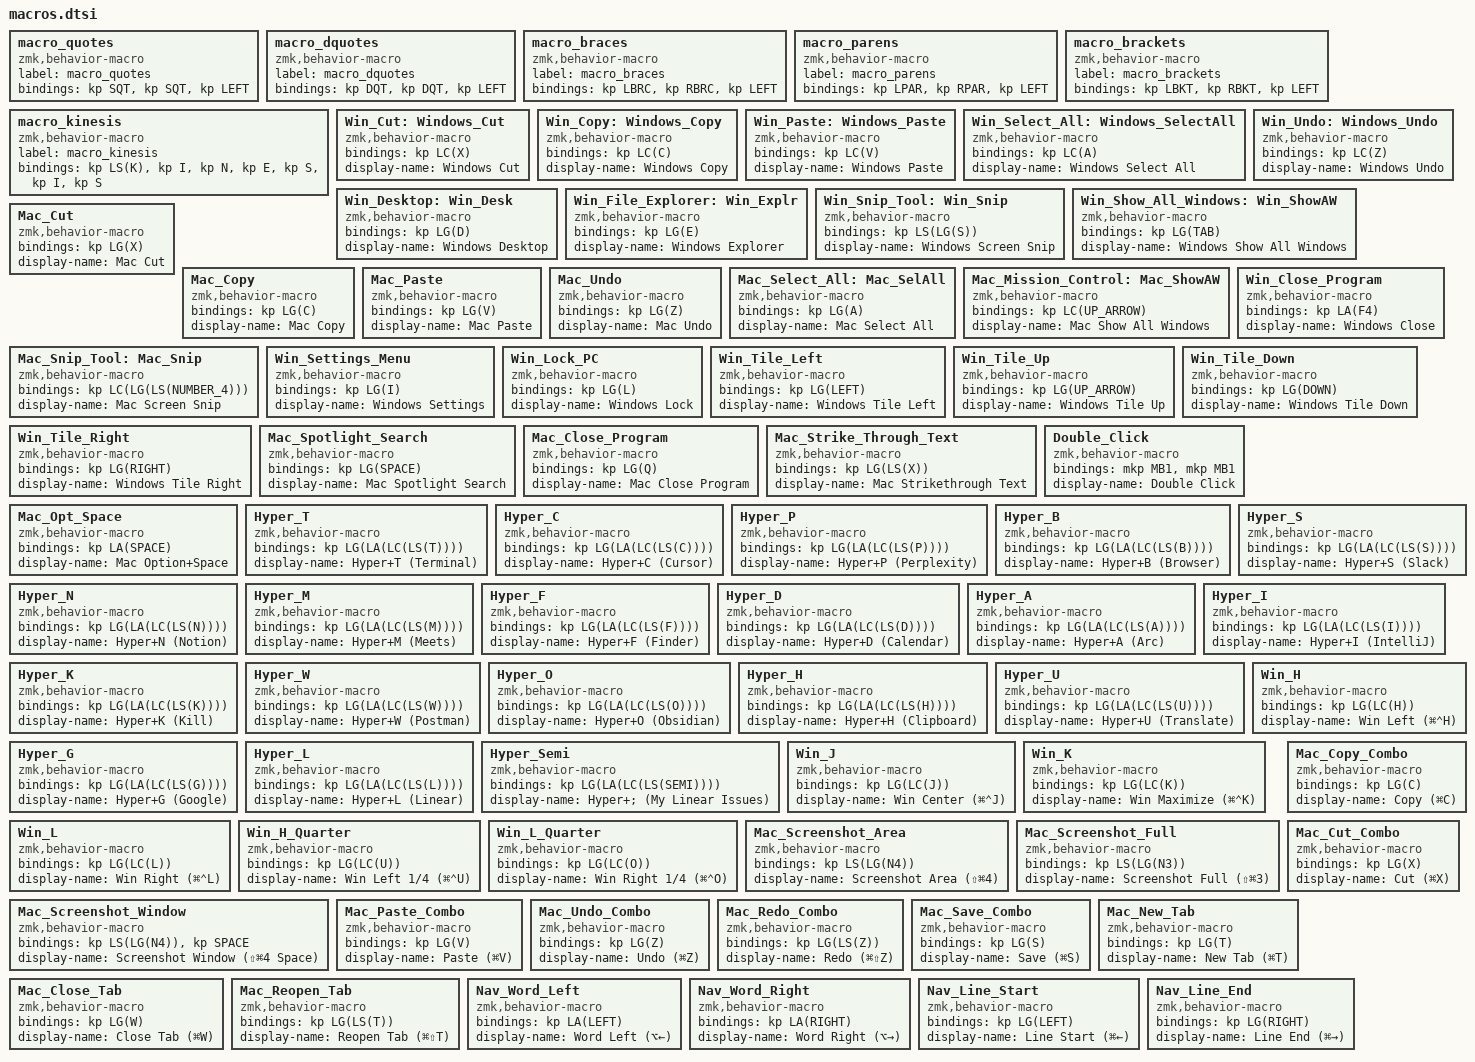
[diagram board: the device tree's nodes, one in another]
  macro_quotes: macro_quotes {
    compatible = "zmk,behavior-macro";
    label = "macro_quotes";
    #binding-cells = <0>;
    bindings = <&kp SQT>, <&kp SQT>, <&kp LEFT>;
  };
  macro_dquotes: macro_dquotes {
    compatible = "zmk,behavior-macro";
    label = "macro_dquotes";
    #binding-cells = <0>;
    bindings = <&kp DQT>, <&kp DQT>, <&kp LEFT>;
  };
  macro_braces: macro_braces {
    compatible = "zmk,behavior-macro";
    label = "macro_braces";
    #binding-cells = <0>;
    bindings = <&kp LBRC>, <&kp RBRC>, <&kp LEFT>;
  };
  macro_parens: macro_parens {
    compatible = "zmk,behavior-macro";
    label = "macro_parens";
    #binding-cells = <0>;
    bindings = <&kp LPAR>, <&kp RPAR>, <&kp LEFT>;
  };
  macro_brackets: macro_brackets {
    compatible = "zmk,behavior-macro";
    label = "macro_brackets";
    #binding-cells = <0>;
    bindings = <&kp LBKT>, <&kp RBKT>, <&kp LEFT>;
  };
  macro_kinesis: macro_kinesis {
    compatible = "zmk,behavior-macro";
    label = "macro_kinesis";
    #binding-cells = <0>;
    bindings = <&kp LS(K)>, <&kp I>, <&kp N>, <&kp E>, <&kp S>, <&kp I>, <&kp S>;
  };
  Win_Cut: Windows_Cut {
    compatible = "zmk,behavior-macro";
    #binding-cells = <0>;
    bindings = <&kp LC(X)>;
    display-name = "Windows Cut";
  };

  Win_Copy: Windows_Copy {
    compatible = "zmk,behavior-macro";
    #binding-cells = <0>;
    bindings = <&kp LC(C)>;
    display-name = "Windows Copy";
  };

  Win_Paste: Windows_Paste {
    compatible = "zmk,behavior-macro";
    #binding-cells = <0>;
    bindings = <&kp LC(V)>;
    display-name = "Windows Paste";
  };

  Win_Select_All: Windows_SelectAll {
      compatible = "zmk,behavior-macro";
      #binding-cells = <0>;
      bindings = <&kp LC(A)>;
      display-name = "Windows Select All";
  };

  Win_Undo: Windows_Undo {
    compatible = "zmk,behavior-macro";
    #binding-cells = <0>;
    bindings = <&kp LC(Z)>;
    display-name = "Windows Undo";
  };

  Win_Desktop: Win_Desk {
    compatible = "zmk,behavior-macro";
    #binding-cells = <0>;
    bindings = <&kp LG(D)>;
    display-name = "Windows Desktop";
  };

  Win_File_Explorer: Win_Explr {
    compatible = "zmk,behavior-macro";
    #binding-cells = <0>;
    bindings = <&kp LG(E)>;
    display-name = "Windows Explorer";
  };

  Win_Snip_Tool: Win_Snip {
    compatible = "zmk,behavior-macro";
    #binding-cells = <0>;
    bindings = <&kp LS(LG(S))>;
    display-name = "Windows Screen Snip";
  };

  Win_Show_All_Windows: Win_ShowAW {
    compatible = "zmk,behavior-macro";
    #binding-cells = <0>;
    bindings = <&kp LG(TAB)>;
    display-name = "Windows Show All Windows";
  };

  Mac_Cut: Mac_Cut {
    compatible = "zmk,behavior-macro";
    #binding-cells = <0>;
    bindings = <&kp LG(X)>;
    display-name = "Mac Cut";
  };

  Mac_Copy: Mac_Copy {
    compatible = "zmk,behavior-macro";
    #binding-cells = <0>;
    bindings = <&kp LG(C)>;
    display-name = "Mac Copy";
  };

  Mac_Paste: Mac_Paste {
    compatible = "zmk,behavior-macro";
    #binding-cells = <0>;
    bindings = <&kp LG(V)>;
    display-name = "Mac Paste";
  };

  Mac_Undo: Mac_Undo {
    compatible = "zmk,behavior-macro";
    #binding-cells = <0>;
    bindings = <&kp LG(Z)>;
    display-name = "Mac Undo";
  };

  Mac_Select_All: Mac_SelAll {
    compatible = "zmk,behavior-macro";
    #binding-cells = <0>;
    bindings = <&kp LG(A)>;
    display-name = "Mac Select All";
  };

  Mac_Mission_Control: Mac_ShowAW {
    compatible = "zmk,behavior-macro";
    #binding-cells = <0>;
    bindings = <&kp LC(UP_ARROW)>;
    display-name = "Mac Show All Windows";
  };

  Mac_Snip_Tool: Mac_Snip {
    compatible = "zmk,behavior-macro";
    #binding-cells = <0>;
    bindings = <&kp LC(LG(LS(NUMBER_4)))>;
    display-name = "Mac Screen Snip";
  };

  Win_Close_Program: Win_Close_Program {
    compatible = "zmk,behavior-macro";
    #binding-cells = <0>;
    bindings = <&kp LA(F4)>;
    display-name = "Windows Close";
  };

  Win_Settings_Menu: Win_Settings_Menu {
    compatible = "zmk,behavior-macro";
    #binding-cells = <0>;
    bindings = <&kp LG(I)>;
    display-name = "Windows Settings";
  };

  Win_Lock_PC: Win_Lock_PC {
    compatible = "zmk,behavior-macro";
    #binding-cells = <0>;
    bindings = <&kp LG(L)>;
    display-name = "Windows Lock";
  };

  Win_Tile_Left: Win_Tile_Left {
    compatible = "zmk,behavior-macro";
    #binding-cells = <0>;
    bindings = <&kp LG(LEFT)>;
    display-name = "Windows Tile Left";
  };

  Win_Tile_Up: Win_Tile_Up {
    compatible = "zmk,behavior-macro";
    #binding-cells = <0>;
    bindings = <&kp LG(UP_ARROW)>;
    display-name = "Windows Tile Up";
  };

  Win_Tile_Down: Win_Tile_Down {
    compatible = "zmk,behavior-macro";
    #binding-cells = <0>;
    bindings = <&kp LG(DOWN)>;
    display-name = "Windows Tile Down";
  };

  Win_Tile_Right: Win_Tile_Right {
    compatible = "zmk,behavior-macro";
    #binding-cells = <0>;
    bindings = <&kp LG(RIGHT)>;
    display-name = "Windows Tile Right";
  };

  Mac_Spotlight_Search: Mac_Spotlight_Search {
    compatible = "zmk,behavior-macro";
    #binding-cells = <0>;
    bindings = <&kp LG(SPACE)>;
    display-name = "Mac Spotlight Search";
  };

  Mac_Close_Program: Mac_Close_Program {
    compatible = "zmk,behavior-macro";
    #binding-cells = <0>;
    bindings = <&kp LG(Q)>;
    display-name = "Mac Close Program";
  };

  Mac_Strike_Through_Text: Mac_Strike_Through_Text {
    compatible = "zmk,behavior-macro";
    #binding-cells = <0>;
    bindings = <&kp LG(LS(X))>;
    display-name = "Mac Strikethrough Text";
  };

  Double_Click: Double_Click {
    compatible = "zmk,behavior-macro";
    #binding-cells = <0>;
    bindings = <&mkp MB1 &mkp MB1>;
    display-name = "Double Click";
  };

  Mac_Opt_Space: Mac_Opt_Space {
    compatible = "zmk,behavior-macro";
    #binding-cells = <0>;
    bindings = <&kp LA(SPACE)>;
    display-name = "Mac Option+Space";
  };

  // Hyper key app launchers (Cmd+Opt+Ctrl+Shift+Letter)
  Hyper_T: Hyper_T {
    compatible = "zmk,behavior-macro";
    #binding-cells = <0>;
    bindings = <&kp LG(LA(LC(LS(T))))>;
    display-name = "Hyper+T (Terminal)";
  };

  Hyper_C: Hyper_C {
    compatible = "zmk,behavior-macro";
    #binding-cells = <0>;
    bindings = <&kp LG(LA(LC(LS(C))))>;
    display-name = "Hyper+C (Cursor)";
  };

  Hyper_P: Hyper_P {
    compatible = "zmk,behavior-macro";
    #binding-cells = <0>;
    bindings = <&kp LG(LA(LC(LS(P))))>;
    display-name = "Hyper+P (Perplexity)";
  };

  Hyper_B: Hyper_B {
    compatible = "zmk,behavior-macro";
    #binding-cells = <0>;
    bindings = <&kp LG(LA(LC(LS(B))))>;
    display-name = "Hyper+B (Browser)";
  };

  Hyper_S: Hyper_S {
    compatible = "zmk,behavior-macro";
    #binding-cells = <0>;
    bindings = <&kp LG(LA(LC(LS(S))))>;
    display-name = "Hyper+S (Slack)";
  };

  Hyper_N: Hyper_N {
    compatible = "zmk,behavior-macro";
    #binding-cells = <0>;
    bindings = <&kp LG(LA(LC(LS(N))))>;
    display-name = "Hyper+N (Notion)";
  };

  Hyper_M: Hyper_M {
    compatible = "zmk,behavior-macro";
    #binding-cells = <0>;
    bindings = <&kp LG(LA(LC(LS(M))))>;
    display-name = "Hyper+M (Meets)";
  };

  Hyper_F: Hyper_F {
    compatible = "zmk,behavior-macro";
    #binding-cells = <0>;
    bindings = <&kp LG(LA(LC(LS(F))))>;
    display-name = "Hyper+F (Finder)";
  };

  Hyper_D: Hyper_D {
    compatible = "zmk,behavior-macro";
    #binding-cells = <0>;
    bindings = <&kp LG(LA(LC(LS(D))))>;
    display-name = "Hyper+D (Calendar)";
  };

  Hyper_A: Hyper_A {
    compatible = "zmk,behavior-macro";
    #binding-cells = <0>;
    bindings = <&kp LG(LA(LC(LS(A))))>;
    display-name = "Hyper+A (Arc)";
  };

  Hyper_I: Hyper_I {
    compatible = "zmk,behavior-macro";
    #binding-cells = <0>;
    bindings = <&kp LG(LA(LC(LS(I))))>;
    display-name = "Hyper+I (IntelliJ)";
  };

  Hyper_K: Hyper_K {
    compatible = "zmk,behavior-macro";
    #binding-cells = <0>;
    bindings = <&kp LG(LA(LC(LS(K))))>;
    display-name = "Hyper+K (Kill)";
  };

  Hyper_W: Hyper_W {
    compatible = "zmk,behavior-macro";
    #binding-cells = <0>;
    bindings = <&kp LG(LA(LC(LS(W))))>;
    display-name = "Hyper+W (Postman)";
  };

  Hyper_O: Hyper_O {
    compatible = "zmk,behavior-macro";
    #binding-cells = <0>;
    bindings = <&kp LG(LA(LC(LS(O))))>;
    display-name = "Hyper+O (Obsidian)";
  };

  Hyper_H: Hyper_H {
    compatible = "zmk,behavior-macro";
    #binding-cells = <0>;
    bindings = <&kp LG(LA(LC(LS(H))))>;
    display-name = "Hyper+H (Clipboard)";
  };

  Hyper_U: Hyper_U {
    compatible = "zmk,behavior-macro";
    #binding-cells = <0>;
    bindings = <&kp LG(LA(LC(LS(U))))>;
    display-name = "Hyper+U (Translate)";
  };

  Hyper_G: Hyper_G {
    compatible = "zmk,behavior-macro";
    #binding-cells = <0>;
    bindings = <&kp LG(LA(LC(LS(G))))>;
    display-name = "Hyper+G (Google)";
  };

  Hyper_L: Hyper_L {
    compatible = "zmk,behavior-macro";
    #binding-cells = <0>;
    bindings = <&kp LG(LA(LC(LS(L))))>;
    display-name = "Hyper+L (Linear)";
  };

  Hyper_Semi: Hyper_Semi {
    compatible = "zmk,behavior-macro";
    #binding-cells = <0>;
    bindings = <&kp LG(LA(LC(LS(SEMI))))>;
    display-name = "Hyper+; (My Linear Issues)";
  };

  // Window Management shortcuts (Cmd+Ctrl+Letter)
  Win_H: Win_H {
    compatible = "zmk,behavior-macro";
    #binding-cells = <0>;
    bindings = <&kp LG(LC(H))>;
    display-name = "Win Left (⌘⌃H)";
  };

  Win_J: Win_J {
    compatible = "zmk,behavior-macro";
    #binding-cells = <0>;
    bindings = <&kp LG(LC(J))>;
    display-name = "Win Center (⌘⌃J)";
  };

  Win_K: Win_K {
    compatible = "zmk,behavior-macro";
    #binding-cells = <0>;
    bindings = <&kp LG(LC(K))>;
    display-name = "Win Maximize (⌘⌃K)";
  };

  Win_L: Win_L {
    compatible = "zmk,behavior-macro";
    #binding-cells = <0>;
    bindings = <&kp LG(LC(L))>;
    display-name = "Win Right (⌘⌃L)";
  };

  Win_H_Quarter: Win_H_Quarter {
    compatible = "zmk,behavior-macro";
    #binding-cells = <0>;
    bindings = <&kp LG(LC(U))>;
    display-name = "Win Left 1/4 (⌘⌃U)";
  };

  Win_L_Quarter: Win_L_Quarter {
    compatible = "zmk,behavior-macro";
    #binding-cells = <0>;
    bindings = <&kp LG(LC(O))>;
    display-name = "Win Right 1/4 (⌘⌃O)";
  };

  // Screenshot macros
  Mac_Screenshot_Area: Mac_Screenshot_Area {
    compatible = "zmk,behavior-macro";
    #binding-cells = <0>;
    bindings = <&kp LS(LG(N4))>;
    display-name = "Screenshot Area (⇧⌘4)";
  };

  Mac_Screenshot_Full: Mac_Screenshot_Full {
    compatible = "zmk,behavior-macro";
    #binding-cells = <0>;
    bindings = <&kp LS(LG(N3))>;
    display-name = "Screenshot Full (⇧⌘3)";
  };

  Mac_Screenshot_Window: Mac_Screenshot_Window {
    compatible = "zmk,behavior-macro";
    #binding-cells = <0>;
    bindings = <&kp LS(LG(N4)) &kp SPACE>;
    display-name = "Screenshot Window (⇧⌘4 Space)";
  };

  // Common action macros for combos
  Mac_Copy_Combo: Mac_Copy_Combo {
    compatible = "zmk,behavior-macro";
    #binding-cells = <0>;
    bindings = <&kp LG(C)>;
    display-name = "Copy (⌘C)";
  };

  Mac_Paste_Combo: Mac_Paste_Combo {
    compatible = "zmk,behavior-macro";
    #binding-cells = <0>;
    bindings = <&kp LG(V)>;
    display-name = "Paste (⌘V)";
  };

  Mac_Cut_Combo: Mac_Cut_Combo {
    compatible = "zmk,behavior-macro";
    #binding-cells = <0>;
    bindings = <&kp LG(X)>;
    display-name = "Cut (⌘X)";
  };

  Mac_Undo_Combo: Mac_Undo_Combo {
    compatible = "zmk,behavior-macro";
    #binding-cells = <0>;
    bindings = <&kp LG(Z)>;
    display-name = "Undo (⌘Z)";
  };

  Mac_Redo_Combo: Mac_Redo_Combo {
    compatible = "zmk,behavior-macro";
    #binding-cells = <0>;
    bindings = <&kp LG(LS(Z))>;
    display-name = "Redo (⌘⇧Z)";
  };

  Mac_Save_Combo: Mac_Save_Combo {
    compatible = "zmk,behavior-macro";
    #binding-cells = <0>;
    bindings = <&kp LG(S)>;
    display-name = "Save (⌘S)";
  };

  Mac_New_Tab: Mac_New_Tab {
    compatible = "zmk,behavior-macro";
    #binding-cells = <0>;
    bindings = <&kp LG(T)>;
    display-name = "New Tab (⌘T)";
  };

  Mac_Close_Tab: Mac_Close_Tab {
    compatible = "zmk,behavior-macro";
    #binding-cells = <0>;
    bindings = <&kp LG(W)>;
    display-name = "Close Tab (⌘W)";
  };

  Mac_Reopen_Tab: Mac_Reopen_Tab {
    compatible = "zmk,behavior-macro";
    #binding-cells = <0>;
    bindings = <&kp LG(LS(T))>;
    display-name = "Reopen Tab (⌘⇧T)";
  };

  // Navigation macros
  Nav_Word_Left: Nav_Word_Left {
    compatible = "zmk,behavior-macro";
    #binding-cells = <0>;
    bindings = <&kp LA(LEFT)>;
    display-name = "Word Left (⌥←)";
  };

  Nav_Word_Right: Nav_Word_Right {
    compatible = "zmk,behavior-macro";
    #binding-cells = <0>;
    bindings = <&kp LA(RIGHT)>;
    display-name = "Word Right (⌥→)";
  };

  Nav_Line_Start: Nav_Line_Start {
    compatible = "zmk,behavior-macro";
    #binding-cells = <0>;
    bindings = <&kp LG(LEFT)>;
    display-name = "Line Start (⌘←)";
  };

  Nav_Line_End: Nav_Line_End {
    compatible = "zmk,behavior-macro";
    #binding-cells = <0>;
    bindings = <&kp LG(RIGHT)>;
    display-name = "Line End (⌘→)";
  };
